AUTOSAR XML (schema 00046)
package /ComponentTypes
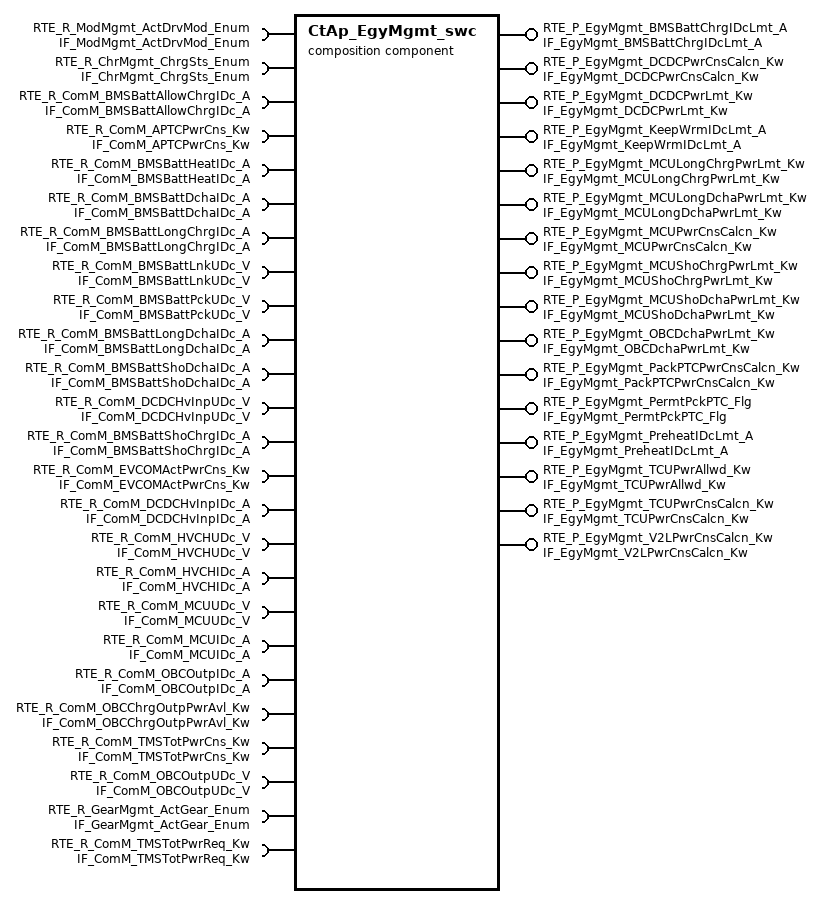
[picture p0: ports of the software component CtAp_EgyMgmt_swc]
  composition sw component type CtAp_EgyMgmt_swc
    16 x provide port:
      RTE_P_EgyMgmt_BMSBattChrgIDcLmt_A: nonqueued-sender-com-spec{data-element=tec_EgyMgmt_BMSBattChrgIDcLmt_A, init-value=0}, provided-interface=IF_EgyMgmt_BMSBattChrgIDcLmt_A
      RTE_P_EgyMgmt_DCDCPwrCnsCalcn_Kw: nonqueued-sender-com-spec{data-element=tec_EgyMgmt_DCDCPwrCnsCalcn_Kw, init-value=0}, provided-interface=IF_EgyMgmt_DCDCPwrCnsCalcn_Kw
      RTE_P_EgyMgmt_DCDCPwrLmt_Kw: nonqueued-sender-com-spec{data-element=tec_EgyMgmt_DCDCPwrLmt_Kw, init-value=0}, provided-interface=IF_EgyMgmt_DCDCPwrLmt_Kw
      RTE_P_EgyMgmt_KeepWrmIDcLmt_A: nonqueued-sender-com-spec{data-element=tec_EgyMgmt_KeepWrmIDcLmt_A, init-value=0}, provided-interface=IF_EgyMgmt_KeepWrmIDcLmt_A
      RTE_P_EgyMgmt_MCULongChrgPwrLmt_Kw: nonqueued-sender-com-spec{data-element=tec_EgyMgmt_MCULongChrgPwrLmt_Kw, init-value=0}, provided-interface=IF_EgyMgmt_MCULongChrgPwrLmt_Kw
      RTE_P_EgyMgmt_MCULongDchaPwrLmt_Kw: nonqueued-sender-com-spec{data-element=tec_EgyMgmt_MCULongDchaPwrLmt_Kw, init-value=0}, provided-interface=IF_EgyMgmt_MCULongDchaPwrLmt_Kw
      RTE_P_EgyMgmt_MCUPwrCnsCalcn_Kw: nonqueued-sender-com-spec{data-element=tec_EgyMgmt_MCUPwrCnsCalcn_Kw, init-value=0}, provided-interface=IF_EgyMgmt_MCUPwrCnsCalcn_Kw
      RTE_P_EgyMgmt_MCUShoChrgPwrLmt_Kw: nonqueued-sender-com-spec{data-element=tec_EgyMgmt_MCUShoChrgPwrLmt_Kw, init-value=0}, provided-interface=IF_EgyMgmt_MCUShoChrgPwrLmt_Kw
      RTE_P_EgyMgmt_MCUShoDchaPwrLmt_Kw: nonqueued-sender-com-spec{data-element=tec_EgyMgmt_MCUShoDchaPwrLmt_Kw, init-value=0}, provided-interface=IF_EgyMgmt_MCUShoDchaPwrLmt_Kw
      RTE_P_EgyMgmt_OBCDchaPwrLmt_Kw: nonqueued-sender-com-spec{data-element=tec_EgyMgmt_OBCDchaPwrLmt_Kw, init-value=0}, provided-interface=IF_EgyMgmt_OBCDchaPwrLmt_Kw
      RTE_P_EgyMgmt_PackPTCPwrCnsCalcn_Kw: nonqueued-sender-com-spec{data-element=tec_EgyMgmt_PackPTCPwrCnsCalcn_Kw, init-value=0}, provided-interface=IF_EgyMgmt_PackPTCPwrCnsCalcn_Kw
      RTE_P_EgyMgmt_PermtPckPTC_Flg: nonqueued-sender-com-spec{data-element=tec_EgyMgmt_PermtPckPTC_Flg, init-value=0}, provided-interface=IF_EgyMgmt_PermtPckPTC_Flg
      RTE_P_EgyMgmt_PreheatIDcLmt_A: nonqueued-sender-com-spec{data-element=tec_EgyMgmt_PreheatIDcLmt_A, init-value=0}, provided-interface=IF_EgyMgmt_PreheatIDcLmt_A
      RTE_P_EgyMgmt_TCUPwrAllwd_Kw: nonqueued-sender-com-spec{data-element=tec_EgyMgmt_TCUPwrAllwd_Kw, init-value=0}, provided-interface=IF_EgyMgmt_TCUPwrAllwd_Kw
      RTE_P_EgyMgmt_TCUPwrCnsCalcn_Kw: nonqueued-sender-com-spec{data-element=tec_EgyMgmt_TCUPwrCnsCalcn_Kw, init-value=0}, provided-interface=IF_EgyMgmt_TCUPwrCnsCalcn_Kw
      RTE_P_EgyMgmt_V2LPwrCnsCalcn_Kw: nonqueued-sender-com-spec{data-element=IF_EgyMgmt_V2LPwrCnsCalcn_Kw, init-value=0}, provided-interface=IF_EgyMgmt_V2LPwrCnsCalcn_Kw
    25 x require port:
      RTE_R_ModMgmt_ActDrvMod_Enum: nonqueued-receiver-com-spec{data-element=tec_ModMgmt_ActDrvMod_Enum, filter=data-filter-type=ALWAYS, init-value=0}, required-interface=IF_ModMgmt_ActDrvMod_Enum
      RTE_R_ChrMgmt_ChrgSts_Enum: nonqueued-receiver-com-spec{data-element=tec_ChrMgmt_ChrgSts_Enum, filter=data-filter-type=ALWAYS, init-value=0}, required-interface=IF_ChrMgmt_ChrgSts_Enum
      RTE_R_ComM_BMSBattAllowChrgIDc_A: nonqueued-receiver-com-spec{data-element=tec_ComM_BMSBattAllowChrgIDc_A, filter=data-filter-type=ALWAYS, init-value=0}, required-interface=IF_ComM_BMSBattAllowChrgIDc_A
      RTE_R_ComM_APTCPwrCns_Kw: nonqueued-receiver-com-spec{data-element=tec_ComM_APTCPwrCns_Kw, filter=data-filter-type=ALWAYS, init-value=0}, required-interface=IF_ComM_APTCPwrCns_Kw
      RTE_R_ComM_BMSBattHeatIDc_A: nonqueued-receiver-com-spec{data-element=tec_ComM_BMSBattHeatIDc_A, filter=data-filter-type=ALWAYS, init-value=0}, required-interface=IF_ComM_BMSBattHeatIDc_A
      RTE_R_ComM_BMSBattDchaIDc_A: nonqueued-receiver-com-spec{data-element=tec_ComM_BMSBattDchaIDc_A, filter=data-filter-type=ALWAYS, init-value=0}, required-interface=IF_ComM_BMSBattDchaIDc_A
      RTE_R_ComM_BMSBattLongChrgIDc_A: nonqueued-receiver-com-spec{data-element=tec_ComM_BMSBattLongChrgIDc_A, filter=data-filter-type=ALWAYS, init-value=0}, required-interface=IF_ComM_BMSBattLongChrgIDc_A
      RTE_R_ComM_BMSBattLnkUDc_V: nonqueued-receiver-com-spec{data-element=tec_ComM_BMSBattLnkUDc_V, filter=data-filter-type=ALWAYS, init-value=0}, required-interface=IF_ComM_BMSBattLnkUDc_V
      RTE_R_ComM_BMSBattPckUDc_V: nonqueued-receiver-com-spec{data-element=tec_ComM_BMSBattPckUDc_V, filter=data-filter-type=ALWAYS, init-value=0}, required-interface=IF_ComM_BMSBattPckUDc_V
      RTE_R_ComM_BMSBattLongDchaIDc_A: nonqueued-receiver-com-spec{data-element=tec_ComM_BMSBattLongDchaIDc_A, filter=data-filter-type=ALWAYS, init-value=0}, required-interface=IF_ComM_BMSBattLongDchaIDc_A
      RTE_R_ComM_BMSBattShoDchaIDc_A: nonqueued-receiver-com-spec{data-element=tec_ComM_BMSBattShoDchaIDc_A, filter=data-filter-type=ALWAYS, init-value=0}, required-interface=IF_ComM_BMSBattShoDchaIDc_A
      RTE_R_ComM_DCDCHvInpUDc_V: nonqueued-receiver-com-spec{data-element=tec_ComM_DCDCHvInpUDc_V, filter=data-filter-type=ALWAYS, init-value=0}, required-interface=IF_ComM_DCDCHvInpUDc_V
      RTE_R_ComM_BMSBattShoChrgIDc_A: nonqueued-receiver-com-spec{data-element=tec_ComM_BMSBattShoChrgIDc_A, filter=data-filter-type=ALWAYS, init-value=0}, required-interface=IF_ComM_BMSBattShoChrgIDc_A
      RTE_R_ComM_EVCOMActPwrCns_Kw: nonqueued-receiver-com-spec{data-element=tec_ComM_EVCOMActPwrCns_Kw, filter=data-filter-type=ALWAYS, init-value=0}, required-interface=IF_ComM_EVCOMActPwrCns_Kw
      RTE_R_ComM_DCDCHvInpIDc_A: nonqueued-receiver-com-spec{data-element=tec_ComM_DCDCHvInpIDc_A, filter=data-filter-type=ALWAYS, init-value=0}, required-interface=IF_ComM_DCDCHvInpIDc_A
      RTE_R_ComM_HVCHUDc_V: nonqueued-receiver-com-spec{data-element=tec_ComM_HVCHUDc_V, filter=data-filter-type=ALWAYS, init-value=0}, required-interface=IF_ComM_HVCHUDc_V
      RTE_R_ComM_HVCHIDc_A: nonqueued-receiver-com-spec{data-element=tec_ComM_HVCHIDc_A, filter=data-filter-type=ALWAYS, init-value=0}, required-interface=IF_ComM_HVCHIDc_A
      RTE_R_ComM_MCUUDc_V: nonqueued-receiver-com-spec{data-element=tec_ComM_MCUUDc_V, filter=data-filter-type=ALWAYS, init-value=0}, required-interface=IF_ComM_MCUUDc_V
      RTE_R_ComM_MCUIDc_A: nonqueued-receiver-com-spec{data-element=tec_ComM_MCUIDc_A, filter=data-filter-type=ALWAYS, init-value=0}, required-interface=IF_ComM_MCUIDc_A
      RTE_R_ComM_OBCOutpIDc_A: nonqueued-receiver-com-spec{data-element=tec_ComM_OBCOutpIDc_A, filter=data-filter-type=ALWAYS, init-value=0}, required-interface=IF_ComM_OBCOutpIDc_A
      RTE_R_ComM_OBCChrgOutpPwrAvl_Kw: nonqueued-receiver-com-spec{data-element=tec_ComM_OBCChrgOutpPwrAvl_Kw, filter=data-filter-type=ALWAYS, init-value=0}, required-interface=IF_ComM_OBCChrgOutpPwrAvl_Kw
      RTE_R_ComM_TMSTotPwrCns_Kw: nonqueued-receiver-com-spec{data-element=tec_ComM_TMSTotPwrCns_Kw, filter=data-filter-type=ALWAYS, init-value=0}, required-interface=IF_ComM_TMSTotPwrCns_Kw
      RTE_R_ComM_OBCOutpUDc_V: nonqueued-receiver-com-spec{data-element=tec_ComM_OBCOutpUDc_V, filter=data-filter-type=ALWAYS, init-value=0}, required-interface=IF_ComM_OBCOutpUDc_V
      RTE_R_GearMgmt_ActGear_Enum: nonqueued-receiver-com-spec{data-element=tec_GearMgmt_ActGear_Enum, filter=data-filter-type=ALWAYS, init-value=0}, required-interface=IF_GearMgmt_ActGear_Enum
      RTE_R_ComM_TMSTotPwrReq_Kw: nonqueued-receiver-com-spec{data-element=tec_ComM_TMSTotPwrReq_Kw, filter=data-filter-type=ALWAYS, init-value=0}, required-interface=IF_ComM_TMSTotPwrReq_Kw
    component CtAp_PwrLim: type=CtAp_PwrLim
    component CtAp_CnsCalcn: type=CtAp_CnsCalcn
    delegate CtAp_PwrLim.RTE_P_EgyMgmt_BMSBattChrgIDcLmt_A <-> outer port RTE_P_EgyMgmt_BMSBattChrgIDcLmt_A
    delegate CtAp_CnsCalcn.RTE_P_EgyMgmt_DCDCPwrCnsCalcn_Kw <-> outer port RTE_P_EgyMgmt_DCDCPwrCnsCalcn_Kw
    delegate CtAp_PwrLim.RTE_P_EgyMgmt_DCDCPwrLmt_Kw <-> outer port RTE_P_EgyMgmt_DCDCPwrLmt_Kw
    delegate CtAp_PwrLim.RTE_P_EgyMgmt_KeepWrmIDcLmt_A <-> outer port RTE_P_EgyMgmt_KeepWrmIDcLmt_A
    delegate CtAp_PwrLim.RTE_P_EgyMgmt_MCULongChrgPwrLmt_Kw <-> outer port RTE_P_EgyMgmt_MCULongChrgPwrLmt_Kw
    delegate CtAp_PwrLim.RTE_P_EgyMgmt_MCULongDchaPwrLmt_Kw <-> outer port RTE_P_EgyMgmt_MCULongDchaPwrLmt_Kw
    delegate CtAp_CnsCalcn.RTE_P_EgyMgmt_MCUPwrCnsCalcn_Kw <-> outer port RTE_P_EgyMgmt_MCUPwrCnsCalcn_Kw
    delegate CtAp_PwrLim.RTE_P_EgyMgmt_MCUShoChrgPwrLmt_Kw <-> outer port RTE_P_EgyMgmt_MCUShoChrgPwrLmt_Kw
    delegate CtAp_PwrLim.RTE_P_EgyMgmt_MCUShoDchaPwrLmt_Kw <-> outer port RTE_P_EgyMgmt_MCUShoDchaPwrLmt_Kw
    delegate CtAp_PwrLim.RTE_P_EgyMgmt_OBCDchaPwrLmt_Kw <-> outer port RTE_P_EgyMgmt_OBCDchaPwrLmt_Kw
    delegate CtAp_CnsCalcn.RTE_P_EgyMgmt_PackPTCPwrCnsCalcn_Kw <-> outer port RTE_P_EgyMgmt_PackPTCPwrCnsCalcn_Kw
    delegate CtAp_PwrLim.RTE_P_EgyMgmt_PermtPckPTC_Flg <-> outer port RTE_P_EgyMgmt_PermtPckPTC_Flg
    delegate CtAp_PwrLim.RTE_P_EgyMgmt_PreheatIDcLmt_A <-> outer port RTE_P_EgyMgmt_PreheatIDcLmt_A
    delegate CtAp_PwrLim.RTE_P_EgyMgmt_TCUPwrAllwd_Kw <-> outer port RTE_P_EgyMgmt_TCUPwrAllwd_Kw
    delegate CtAp_CnsCalcn.RTE_P_EgyMgmt_V2LPwrCnsCalcn_Kw <-> outer port RTE_P_EgyMgmt_V2LPwrCnsCalcn_Kw
    delegate CtAp_CnsCalcn.RTE_P_EgyMgmt_TCUPwrCnsCalcn_Kw <-> outer port RTE_P_EgyMgmt_TCUPwrCnsCalcn_Kw
    delegate CtAp_CnsCalcn.RTE_R_ComM_APTCPwrCns_Kw <-> outer port RTE_R_ComM_APTCPwrCns_Kw
    delegate CtAp_CnsCalcn.RTE_R_ComM_BMSBattHeatIDc_A <-> outer port RTE_R_ComM_BMSBattHeatIDc_A
    delegate CtAp_CnsCalcn.RTE_R_ComM_BMSBattLnkUDc_V <-> outer port RTE_R_ComM_BMSBattLnkUDc_V
    delegate CtAp_CnsCalcn.RTE_R_ComM_DCDCHvInpIDc_A <-> outer port RTE_R_ComM_DCDCHvInpIDc_A
    delegate CtAp_CnsCalcn.RTE_R_ComM_DCDCHvInpUDc_V <-> outer port RTE_R_ComM_DCDCHvInpUDc_V
    delegate CtAp_CnsCalcn.RTE_R_ComM_EVCOMActPwrCns_Kw <-> outer port RTE_R_ComM_EVCOMActPwrCns_Kw
    delegate CtAp_CnsCalcn.RTE_R_ComM_HVCHIDc_A <-> outer port RTE_R_ComM_HVCHIDc_A
    delegate CtAp_CnsCalcn.RTE_R_ComM_HVCHUDc_V <-> outer port RTE_R_ComM_HVCHUDc_V
    delegate CtAp_CnsCalcn.RTE_R_ComM_MCUIDc_A <-> outer port RTE_R_ComM_MCUIDc_A
    delegate CtAp_CnsCalcn.RTE_R_ComM_MCUUDc_V <-> outer port RTE_R_ComM_MCUUDc_V
    delegate CtAp_CnsCalcn.RTE_R_ComM_OBCOutpIDc_A <-> outer port RTE_R_ComM_OBCOutpIDc_A
    delegate CtAp_CnsCalcn.RTE_R_ComM_OBCOutpUDc_V <-> outer port RTE_R_ComM_OBCOutpUDc_V
    delegate CtAp_CnsCalcn.RTE_R_ComM_TMSTotPwrCns_Kw <-> outer port RTE_R_ComM_TMSTotPwrCns_Kw
    delegate CtAp_PwrLim.RTE_R_ChrMgmt_ChrgSts_Enum <-> outer port RTE_R_ChrMgmt_ChrgSts_Enum
    delegate CtAp_PwrLim.RTE_R_ComM_BMSBattAllowChrgIDc_A <-> outer port RTE_R_ComM_BMSBattAllowChrgIDc_A
    delegate CtAp_PwrLim.RTE_R_ComM_BMSBattDchaIDc_A <-> outer port RTE_R_ComM_BMSBattDchaIDc_A
    delegate CtAp_PwrLim.RTE_R_ComM_BMSBattLnkUDc_V <-> outer port RTE_R_ComM_BMSBattLnkUDc_V
    delegate CtAp_PwrLim.RTE_R_ComM_BMSBattLongChrgIDc_A <-> outer port RTE_R_ComM_BMSBattLongChrgIDc_A
    delegate CtAp_PwrLim.RTE_R_ComM_BMSBattLongDchaIDc_A <-> outer port RTE_R_ComM_BMSBattLongDchaIDc_A
    delegate CtAp_PwrLim.RTE_R_ComM_BMSBattPckUDc_V <-> outer port RTE_R_ComM_BMSBattPckUDc_V
    delegate CtAp_PwrLim.RTE_R_ComM_BMSBattShoChrgIDc_A <-> outer port RTE_R_ComM_BMSBattShoChrgIDc_A
    delegate CtAp_PwrLim.RTE_R_ComM_BMSBattShoDchaIDc_A <-> outer port RTE_R_ComM_BMSBattShoDchaIDc_A
    delegate CtAp_PwrLim.RTE_R_ComM_OBCChrgOutpPwrAvl_Kw <-> outer port RTE_R_ComM_OBCChrgOutpPwrAvl_Kw
    delegate CtAp_PwrLim.RTE_R_ComM_TMSTotPwrReq_Kw <-> outer port RTE_R_ComM_TMSTotPwrReq_Kw
    connect CtAp_CnsCalcn.RTE_P_EgyMgmt_DCDCPwrCnsCalcn_Kw -> CtAp_PwrLim.RTE_R_EgyMgmt_DCDCPwrCnsCalcn_Kw
    connect CtAp_CnsCalcn.RTE_P_EgyMgmt_MCUPwrCnsCalcn_Kw -> CtAp_PwrLim.RTE_R_EgyMgmt_MCUPwrCnsCalcn_Kw
    connect CtAp_CnsCalcn.RTE_P_EgyMgmt_PackPTCPwrCnsCalcn_Kw -> CtAp_PwrLim.RTE_R_EgyMgmt_PackPTCPwrCnsCalcn_Kw
    connect CtAp_CnsCalcn.RTE_P_EgyMgmt_TCUPwrCnsCalcn_Kw -> CtAp_PwrLim.RTE_R_EgyMgmt_TCUPwrCnsCalcn_Kw
    connect CtAp_CnsCalcn.RTE_P_EgyMgmt_V2LPwrCnsCalcn_Kw -> CtAp_PwrLim.RTE_R_EgyMgmt_V2LPwrCnsCalcn_Kw
    delegate CtAp_PwrLim.RTE_R_GearMgmt_ActGear_Enum <-> outer port RTE_R_GearMgmt_ActGear_Enum
    delegate CtAp_PwrLim.RTE_R_ModMgmt_ActDrvMod_Enum <-> outer port RTE_R_ModMgmt_ActDrvMod_Enum
